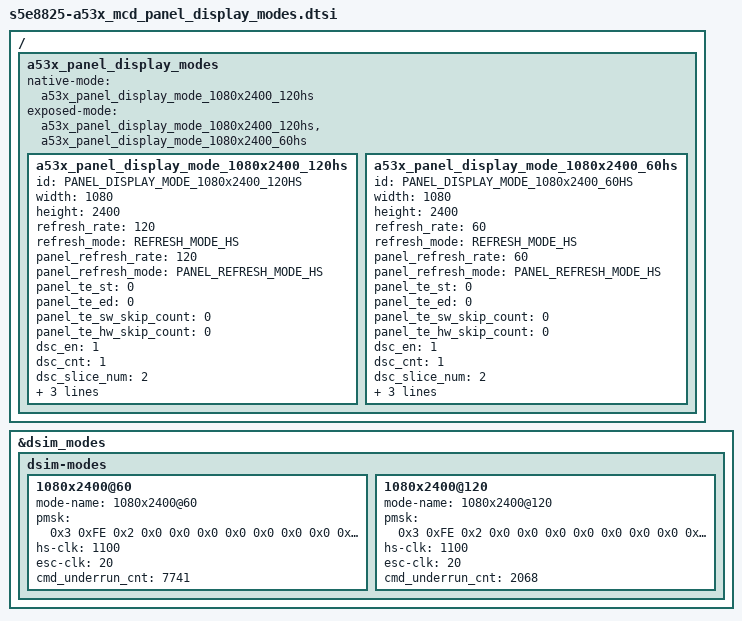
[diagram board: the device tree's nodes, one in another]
/*
 * SAMSUNG LCD Panel Device Tree Source
 *
 * Copyright (c) 2020 Samsung Electronics Co., Ltd.
 *		http://www.samsung.com
 *
 * This program is free software; you can redistribute it and/or modify
 * it under the terms of the GNU General Public License version 2 as
 * published by the Free Software Foundation.
 */

#include <dt-bindings/display/panel-display.h>

&dsim_modes {
	dsim-modes {
		1080x2400@60 {
			mode-name = "1080x2400@60";
			pmsk = <
				0x3 0xFE 0x2 0x0 /* p m s k */
				0x0 0x0 0x0 0x0
				0x0 0x0 0x0 0x0
				0x0 0x0
				>;
			hs-clk = <1100>;
			esc-clk = <20>;
			cmd_underrun_cnt = <7741>;
		};
		1080x2400@120 {
			mode-name = "1080x2400@120";
			pmsk = <
				0x3 0xFE 0x2 0x0 /* p m s k */
				0x0 0x0 0x0 0x0
				0x0 0x0 0x0 0x0
				0x0 0x0
				>;
			hs-clk = <1100>;
			esc-clk = <20>;
			cmd_underrun_cnt = <2068>;
		};
	};
};

/ {
	fragment@panel_display_mode {
		target-path = "/";
		__overlay__ {
			a53x_panel_display_modes:
			a53x_panel_display_modes {
				native-mode = <&a53x_panel_display_mode_1080x2400_120hs>;
				exposed-mode = <
					&a53x_panel_display_mode_1080x2400_120hs
					&a53x_panel_display_mode_1080x2400_60hs
				>;

				/* fhd */
				a53x_panel_display_mode_1080x2400_120hs:
				a53x_panel_display_mode_1080x2400_120hs {
					id = PANEL_DISPLAY_MODE_1080x2400_120HS;
					width = <1080>;
					height = <2400>;
					/* timing parameters */
					refresh_rate = <120>;			/* logical refresh rate */
					refresh_mode = <REFRESH_MODE_HS>;
					panel_refresh_rate = <120>;		/* panel internal refresh rate */
					panel_refresh_mode = <PANEL_REFRESH_MODE_HS>;
					panel_te_st = <0>;				/* te rising */
					panel_te_ed = <0>;				/* te falling */
					panel_te_sw_skip_count = <0>;	/* s/w te modulation */
					panel_te_hw_skip_count = <0>;	/* h/w te modulation */
					/* dsc parameters */
					dsc_en = <1>;			/* 0:Disable, 1:Enable */
					dsc_cnt = <1>;			/* used DSC count */
					dsc_slice_num = <2>;	/* count of dsc slice */
					dsc_slice_w = <540>;	/* width of dsc slice */
					dsc_slice_h = <40>;	/* height of dsc slice */
					/* dsi parameters */
					cmd_lp_ref = <2068>;
				};

				a53x_panel_display_mode_1080x2400_60hs:
				a53x_panel_display_mode_1080x2400_60hs {
					id = PANEL_DISPLAY_MODE_1080x2400_60HS;
					width = <1080>;
					height = <2400>;
					/* timing parameters */
					refresh_rate = <60>;			/* logical refresh rate */
					refresh_mode = <REFRESH_MODE_HS>;
					panel_refresh_rate = <60>;		/* panel internal refresh rate */
					panel_refresh_mode = <PANEL_REFRESH_MODE_HS>;
					panel_te_st = <0>;				/* te rising */
					panel_te_ed = <0>;				/* te falling */
					panel_te_sw_skip_count = <0>;	/* s/w te modulation */
					panel_te_hw_skip_count = <0>;	/* h/w te modulation */
					/* dsc parameters */
					dsc_en = <1>;			/* 0:Disable, 1:Enable */
					dsc_cnt = <1>;			/* used DSC count */
					dsc_slice_num = <2>;	/* count of dsc slice */
					dsc_slice_w = <540>;	/* width of dsc slice */
					dsc_slice_h = <40>;	/* height of dsc slice */
					/* dsi parameters */
					cmd_lp_ref = <7741>;
				};
			};
		};
	};
};
